# PAC52XX register map
Vendor: Active-Semi; Series: PAC52XX; File version: 1.0
CPU: CM0 r0p0, little endian, no MPU, no FPU, vendor SysTick, 2 interrupt priority bits
Registers are 32-bit, read-write, reset 0x0 unless marked. A register's access mark holds for its fields unless they carry their own. Offsets are from the block's base; [hi:lo] are bit positions; {n}, {i} and the like mark numbered series.

## MEMCTL — FLASH Memory Controller
Base 0x40020000
0x00 FLASHLOCK
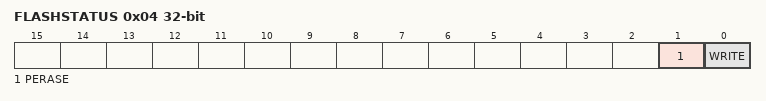
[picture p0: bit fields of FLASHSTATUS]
0x04 FLASHSTATUS
  [1] PERASE — Page Erase Active
    0=inactive (Page erase finished or no page erase in progress); 1=active (Page erase in progress)
  [0] WRITE — Buffered Write Active
    0=inactive (Buffered write inactive); 1=active (Buffered write active)
0x08 FLASHPAGE — FLASH page select register
0x14 FLASHPERASE — FLASH page erase register
0x24 SWDACCESS — SWD access status
0x28 FLASHWSTATE — FLASH Wait State Register
  [1:0] WSTATE — FLASH access wait state
    {v}={v} FLASH wait states (v=0..3)
0x2C FLASHBWRITE — FLASH Buffered Write Data

## WDT — Watchdog Timer
Base 0x40030000
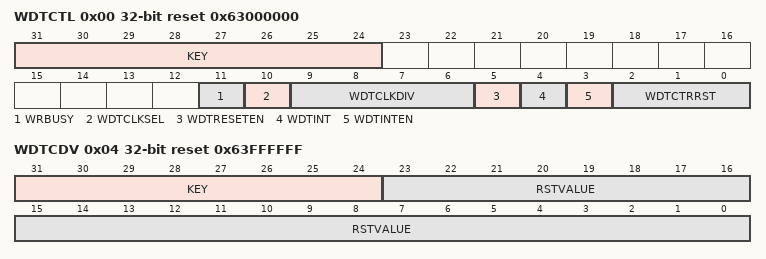
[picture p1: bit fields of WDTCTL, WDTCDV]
0x00 WDTCTL reset 0x63000000 — Watchdog Timer Control Register
  [31:24] KEY — WDTCTL register key
  [11] WRBUSY ro — WDT register write busy
    0=not busy (Watchdog timer register write not busy); 1=busy (Watchdog timer register write busy)
  [10] WDTCLKSEL — Watchdog Timer Input Clock Select
    0=FRCLK (Watchdog timer input clock: FRCLK); 1=FCLK (Watchdog timer input clock: FCLK)
  [9:6] WDTCLKDIV — Watchdog Timer Input Clock Divider
    0=/2 (WDT clock divider: /2); 1=/4 (WDT clock divider: /4); 2=/8 (WDT clock divider: /8); 3=/16 (WDT clock divider: /16); 4=/32 (WDT clock divider: /32); 5=/64 (WDT clock divider: /64); 6=/128 (WDT clock divider: /128); 7=/256 (WDT clock divider: /256); 8=/512 (WDT clock divider: /512); 9=/1024 (WDT clock divider: /1024); 10=/2048 (WDT clock divider: /2048); 11=/4096 (WDT clock divider: /4096); 12=/8192 (WDT clock divider: /8192); 13=/16384 (WDT clock divider: /16384); 14=/32768 (WDT clock divider: /32768); 15=/65536 (WDT clock divider: /65536)
  [5] WDTRESETEN — Watchdog Timer Device Reset Enable
    0=disabled (Watchdog timer device reset disabled); 1=enabled (Watchdog timer device reset enabled)
  [4] WDTINT ro — Watchdog Interval Timer Interrupt Flag
    0=clear (Watchdog timer interrupt flag clear); 1=set (Watchdog timer interrupt flag set)
  [3] WDTINTEN — Watchdog Interval Timer Interrupt Enable
    0=disabled (Watchdog timer interval interrupt disabled); 1=enabled (Watchdog timer interval interrupt enabled)
  [2:0] WDTCTRRST — Watchdog Timer Counter Reset
    5=key (WDTCTL Reset Key)
0x04 WDTCDV reset 0x63FFFFFF — Watchdog Timer Count-down Value Register
  [31:24] KEY — WDTCTL register key
  [23:0] RSTVALUE — 24b WDT count-down value
0x08 WDTCTR ro reset 0xFFFFFF — Watchdog Timer Counter Register

## RTC — Real-Time Clock
Base 0x40040000
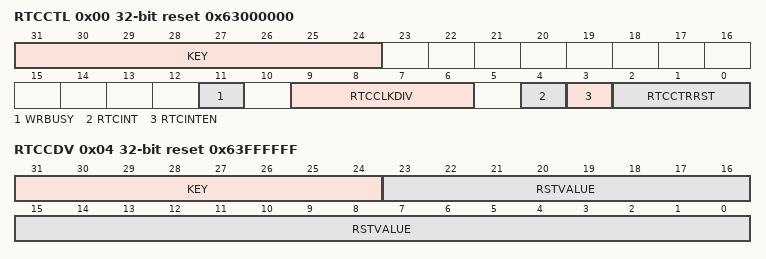
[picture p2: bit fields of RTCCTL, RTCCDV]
0x00 RTCCTL reset 0x63000000 — Real-Time Clock Control Register
  [31:24] KEY — RTCCTL register key
  [11] WRBUSY ro — RTC register write busy
    0=not busy (RTC register write not busy); 1=busy (RTC register write busy)
  [9:6] RTCCLKDIV — Real-Time Clock Input Clock Divider
    0=/2 (Real-Time clock divider: /2); 1=/4 (Real-Time clock divider: /4); 2=/8 (Real-Time clock divider: /8); 3=/16 (Real-Time clock divider: /16); 4=/32 (Real-Time clock divider: /32); 5=/64 (Real-Time clock divider: /64); 6=/128 (Real-Time clock divider: /128); 7=/256 (Real-Time clock divider: /256); 8=/512 (Real-Time clock divider: /512); 9=/1024 (Real-Time clock divider: /1024); 10=/2048 (Real-Time clock divider: /2048); 11=/4096 (Real-Time clock divider: /4096); 12=/8192 (Real-Time clock divider: /8192); 13=/16384 (Real-Time clock divider: /16384); 14=/32768 (Real-Time clock divider: /32768); 15=/65536 (Real-Time clock divider: /65536)
  [4] RTCINT ro — Real-Time Clock Interrupt Flag
    0=clear (Real-Time Clock interrupt flag clear); 1=set (Real-Time Clock interrupt flag set)
  [3] RTCINTEN — Real-Time Clock Interrupt Enable
    0=disabled (Real-Time Clock interrupt disable); 1=enabled (Real-Time Clock interrupt enable)
  [2:0] RTCCTRRST — Real-Time Clock Counter Reset
    5=key (RTCCTL Reset Key)
0x04 RTCCDV reset 0x63FFFFFF — Real-Time Clock Count-down Value Register
  [31:24] KEY — RTC register key
  [23:0] RSTVALUE — 24b RTC count-down value
0x08 RTCCTR ro reset 0xFFFFFF — Real-Time Clock Counter Register

## Notices in the file
Copyright (C) 2015 Active-Semi BVI, Inc. All rights reserved.
THIS SOFTWARE IS SUBJECT TO A SOURCE CODE LICENSE AGREEMENT WHICH PROVIDES,
AMONG OTHER THINGS:  (i) THAT IT CAN BE USED ONLY TO ADAPT THE LICENSEE'S
APPLICATION TO PAC PROCESSORS SUPPLIED BY ACTIVE-SEMI INTERNATIONAL;
(ii) THAT  IT IS PROVIDED "AS IS" WITHOUT WARRANTY;  (iii) THAT
ACTIVE-SEMICONDUCTOR IS NOT LIABLE FOR ANY INDIRECT DAMAGES OR FOR DIRECT
DAMAGES EXCEEDING US$1,500;  AND (iv) THAT IT CAN BE DISCLOSED TO AND USED
ONLY BY CERTAIN AUTHORIZED PERSONS.
